# UART register map
Vendor: Texas Instruments
Peripheral module from a debugger description file (folder am437x).
Registers are 16-bit, access per field, no defined reset value unless marked. A register's access mark holds for its fields unless they carry their own. Offsets are as the file gives them; lines under a group give offsets from that group; [hi:lo] are bit positions; {n}, {i} and the like mark numbered series; 'fields as' and 'values as' point back to an identical list; <NAME> marks a mode.

## UART
0x00 UART_IER_CIR 32-bit access not given
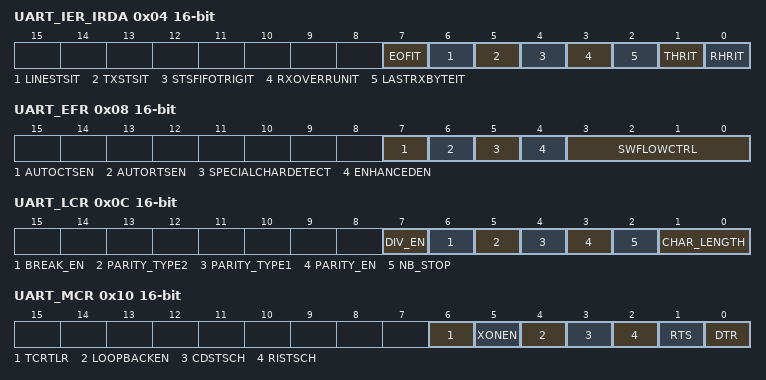
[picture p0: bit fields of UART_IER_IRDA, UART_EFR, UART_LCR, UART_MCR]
0x04 UART_IER_IRDA — The following interrupt enable register (IER) description is for IrDA mode. The IrDA IER is selected with a register bit setting of LCR[7] = 0. In IrDA mode, EFR[4] has no impact on the access to IER[7:4]. The IrDA interrupt enable register (IER) can be programmed to enable/disable any interrupt. There are 8 types of interrupt in these modes, received EOF, LSR interrupt, TX status, status FIFO interrupt, RX overrun, last byte in RX FIFO, THR interrupt, and RHR interrupt. Each interrupt can be enabled/disabled individually. The TXSTATUSIT interrupt reflects two possible conditions. The MDR2[0] bit should be read to determine the status in the event of this interrupt.
  [7] EOFIT rw
    1=en_2_0x1 (Enables the received EOF interrupt.); 0=en_1_0x0 (Disables the received EOF interrupt.)
  [6] LINESTSIT rw
    1=en_2_0x1 (Enables the receiver line status interrupt.); 0=en_1_0x0 (Disables the receiver line status interrupt.)
  [5] TXSTSIT rw — TXSTATUSIT
    1=en_2_0x1 (Enables the TX status interrupt.); 0=en_1_0x0 (Disables the TX status interrupt.)
  [4] STSFIFOTRIGIT rw
    1=en_2_0x1 (Enables status FIFO trigger level interrupt.); 0=en_1_0x0 (Disables status FIFO trigger level interrupt.)
  [3] RXOVERRUNIT rw
    1=en_2_0x1 (Enables the RX overrun interrupt.); 0=en_1_0x0 (Disables the RX overrun interrupt.)
  [2] LASTRXBYTEIT rw
    1=en_2_0x1 (Enables the last byte of frame in RX FIFO interrupt.); 0=en_1_0x0 (Disables the last byte of frame in RX FIFO interrupt.)
  [1] THRIT rw
    1=en_2_0x1 (Enables the THR interrupt.); 0=en_1_0x0 (Disables the THR interrupt.)
  [0] RHRIT rw
    1=en_2_0x1 (Enables the RHR interrupt.); 0=en_1_0x0 (Disables the RHR interrupt.)
0x08 UART_EFR — The enhanced feature register (EFR) is selected with a register bit setting of LCR[7] = BFh. The enhanced feature register (EFR) enables or disables enhanced features. Most enhanced functions apply only to UART modes, but EFR[4] enables write accesses to FCR[5:4], the TX trigger level, which is also used in IrDA modes.
  [7] AUTOCTSEN rw — Auto-CTS enable bit (UART mode only).
    1=en_2_0x1 (Auto-CTS flow control is enabled; transmission is halted when the CTS (active-low) pin is high (inactive).); 0=en_1_0x0 (Normal operation.)
  [6] AUTORTSEN rw — Auto-RTS enable bit (UART mode only).
    1=en_2_0x1 (Auto-RTS flow control is enabled; RTS (active-low) pin goes high (inactive) when the receiver FIFO HALT trigger level, TCR[3:0], is reached and goes low (active) when the receiver FIFO RESTORE transmission trigger level is reached.); 0=en_1_0x0 (Normal operation.)
  [5] SPECIALCHARDETECT rw — Special character detect (UART mode only).
    1=en_2_0x1 (Special character detect enable. Received data is compared with XOFF2 data. If a match occurs, the received data is transferred to RX FIFO and the IIR[4] bit is set to 1 to indicate that a special character was detected.); 0=en_1_0x0 (Normal operation.)
  [4] ENHANCEDEN rw — Enhanced functions write enable bit.
    1=en_2_0x1 (Enables writing to IER[7:4], FCR[5:4], and MCR[7:5].); 0=en_1_0x0 (Disables writing to IER[7:4], FCR[5:4], and MCR[7:5].)
  [3:0] SWFLOWCTRL rw — Combinations of software flow control can be selected by programming this bit. [[br]]XON1 and XON2 should be set to different values if the software flow control is enabled. [[br]]The TX and RX software flow control options are as follows. [[br]]EFR[3] = 0, EFR[2] = 0, EFR[1] = X, and EFR[0] = X, then: No transmit flow control. [[br]]EFR[3] = 1, EFR[2] = 0, EFR[1] = X, and EFR[0] = X, then: Transmit XON1, XOFF1. [[br]]EFR[3] = 0, EFR[2] = 1, EFR[1] = X, and EFR[0] = X, then: Transmit XON2, XOFF2. [[br]]EFR[3] = 1, EFR[2] = 1, EFR[1] = X, and EFR[0] = X, then: Transmit XON1, XON2 or XOFF1, XOFF2. [[br]]The XON1 and XON2 characters or the XOFF1 and XOFF2 characters must be transmitted/received sequentially with XON1/XOFF1 followed by XON2/XOFF2. [[br]]EFR[3] = X, EFR[2] = X, EFR[1] = 0, and EFR[0] = 0, then: No receive flow control. [[br]]EFR[3] = X, EFR[2] = X, EFR[1] = 1, and EFR[0] = 0, then: Receiver compares XON1, XOFF1. [[br]]EFR[3] = X, EFR[2] = X, EFR[1] = 0, and EFR[0] = 1, then: Receiver compares XON2, XOFF2. [[br]]EFR[3] = X, EFR[2] = X, EFR[1] = 1, and EFR[0] = 1, then: Receiver compares XON1, XON2 or XOFF1, XOFF2. [[br]]The XON1 and XON2 characters or the XOFF1 and XOFF2 characters must be transmitted/received sequentially with XON1/XOFF1 followed by XON2/XOFF2. [[br]]In IrDA mode, EFR[1] and EFR[0] select the IR address to check (see IR Address Checking).
0x0C UART_LCR — The line control register (LCR) is selected with a bit register setting of LCR[7] = 0, LCR[7] not equal to BFh, or LCR[7] = BFh. As soon as LCR[6] is set to 1, the TX line is forced to 0 and remains in this state as long as LCR[6] = 1.
  [7] DIV_EN rw — Divisor latch enable.
    1=en_2_0x1 (Divisor latch enable. Allows access to DLL and DLH.); 0=en_1_0x0 (Normal operating condition.)
  [6] BREAK_EN rw — Break control bit. [[br]]Note: When LCR[6] is set to 1, the TX line is forced to 0 and remains in this state as long as LCR[6] = 1.
    1=en_2_0x1 (Forces the transmitter output to go low to alert the communication terminal.); 0=en_1_0x0 (Normal operating condition.)
  [5] PARITY_TYPE2 rw — If LCR[3] = 1, then:
    1=en_2_0x1 (If LCR[5] = 1 and LCR[4] = 0, the parity bit is forced to 1 in the transmitted and received data. If LCR[5] = 1 and LCR[4] = 1, the parity bit is forced to 0 in the transmitted and received data.); 0=en_1_0x0 (If LCR[5] = 0, LCR[4] selects the forced parity format.)
  [4] PARITY_TYPE1 rw — If LCR[3] = 1, then:
    1=en_2_0x1 (Even parity is generated.); 0=en_1_0x0 (Odd parity is generated.)
  [3] PARITY_EN rw — Parity bit.
    1=en_2_0x1 (A parity bit is generated during transmission, and the receiver checks for received parity.); 0=en_1_0x0 (No parity.)
  [2] NB_STOP rw — Specifies the number of stop bits.
    1=en_2_0x1 (1.5 stop bits (word length = 5) or 2 stop bits (word length = 6, 7, 8).); 0=en_1_0x0 (1 stop bit (word length = 5, 6, 7, 8).)
  [1:0] CHAR_LENGTH rw — Specifies the word length to be transmitted or received.
    3=en_4_0x3 (8 bit); 2=en_3_0x2 (7 bits); 1=en_2_0x1 (6 bits); 0=en_1_0x0 (5 bits)
0x10 UART_MCR — The modem control register (MCR) is selected with a register bit setting of LCR[7] = 0 or LCR[7] not equal to BFh. MCR[7:5] can only be written when EFR[4] = 1. Bits 3-0 control the interface with the modem, data set, or peripheral device that is emulating the modem.
  [6] TCRTLR rw — Can be written only when EFR[4] = 1.
    1=en_2_0x1 (Enables access to the TCR and TLR registers.); 0=en_1_0x0 (No action.)
  [5] XONEN rw — Can be written only when EFR[4] = 1.
    1=en_2_0x1 (Enable XON any function.); 0=en_1_0x0 (Disable XON any function.)
  [4] LOOPBACKEN rw — Loopback mode enable.
    1=en_2_0x1 (Enable local loopback mode (internal). In this mode, the MCR[3:0] signals are looped back into MSR[7:4]. The transmit output is looped back to the receive input internally.); 0=en_1_0x0 (Normal operating mode.)
  [3] CDSTSCH rw
    1=en_2_0x1 (In loopback mode, forces DCD (active-low) input low and IRQ outputs to INACTIVE state.); 0=en_1_0x0 (In loopback mode, forces DCD (active-low) input high and IRQ outputs to INACTIVE state.)
  [2] RISTSCH rw
    1=en_2_0x1 (In loopback mode, forces RI (active-low) input active (low).); 0=en_1_0x0 (In loopback mode, forces RI (active-low) input inactive (high).)
  [1] RTS rw — In loopback mode, controls MSR[4]. [[br]]If auto-RTS is enabled, the RTS (active-low) output is controlled by hardware flow control.
    1=en_2_0x1 (Force RTS (active-low) output to active (low).); 0=en_1_0x0 (Force RTS (active-low) output to inactive (high).)
  [0] DTR rw
    1=en_2_0x1 (Force DTR (active-low) output (used in loopback mode) to active (low).); 0=en_1_0x0 (Force DTR (active-low) output (used in loopback mode) to inactive (high).)
0x14 UART_XON2_ADDR2 — The XON2/ADDR2 registers are selected with a register bit setting of LCR[7] = BFh. In UART mode, XON2 character; in IrDA mode, ADDR2 address 2.
  [7:0] XONWORD2 rw — Stores the 8 bit XON2 character in UART modes and ADDR2 address 2 in IrDA modes.
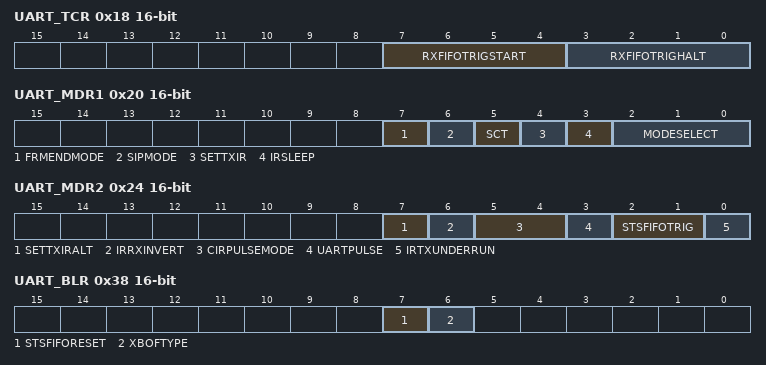
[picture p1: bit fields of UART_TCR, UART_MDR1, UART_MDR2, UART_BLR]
0x18 UART_TCR — The transmission control register (TCR) is selected with a register bit setting of LCR[7] = 0, LCR[7] not equal to BFh, or LCR[7] = BFh. The TCR is accessible only when EFR[4] = 1 and MCR[6] = 1. The transmission control register (TCR) stores the receive FIFO threshold levels to start/stop transmission during hardware flow control. Trigger levels from 0-60 bytes are available with a granularity of 4. Trigger level = 4 x [4-bit register value]. You must ensure that TCR[3:0] > TCR[7:4], whenever auto-RTS or software flow control is enabled to avoid a misoperation of the device. In FIFO interrupt mode with flow control, you have to also ensure that the trigger level to HALT transmission is greater or equal to receive FIFO trigger level (either TLR[7:4] or FCR[7:6]); otherwise, FIFO operation stalls. In FIFO DMA mode with flow control, this concept does not exist because the DMA request is sent each time a byte is received.
  [7:4] RXFIFOTRIGSTART rw — RX FIFO trigger level to RESTORE transmission (0 to 60).
  [3:0] RXFIFOTRIGHALT rw — RX FIFO trigger level to HALT transmission (0 to 60).
0x1C UART_SPR — The scratchpad register (SPR) is selected with a register bit setting of LCR[7] = 0 or LCR[7] not equal to BFh. The scratchpad register (SPR) is a read/write register that does not control the module. It is a scratchpad register used to hold temporary data.
  [7:0] SPR_WORD rw — Scratchpad register.
0x20 UART_MDR1 — The mode definition register 1 (MDR1) is selected with a register bit setting of LCR[7] = 0, LCR[7] not equal to BFh, or LCR[7] = BFh. The mode of operation is programmed by writing to MDR1[2:0]; therefore, the mode definition register 1 (MDR1) must be programmed on startup after configuration of the configuration registers (DLL, DLH, and LCR). The value of MDR1[2:0] must not be changed again during normal operation. If the module is disabled by setting the MODESELECT field to 7h, interrupt requests can still be generated unless disabled through the interrupt enable register (IER). In this case, UART mode interrupts are visible. Reading the interrupt identification register (IIR) shows the UART mode interrupt flags.
  [7] FRMENDMODE rw — IrDA mode only.
    1=en_2_0x1 (Set EOT bit method.); 0=en_1_0x0 (Frame-length method.)
  [6] SIPMODE rw — MIR/FIR modes only.
    1=en_2_0x1 (Automatic SIP mode: SIP is generated after each transmission.); 0=en_1_0x0 (Manual SIP mode: SIP is generated with the control of ACREG[3].)
  [5] SCT rw — Store and control the transmission.
    1=en_2_0x1 (Starts the infrared transmission with the control of ACREG[2]. Note: Before starting any transmission, there must be no reception ongoing.); 0=en_1_0x0 (Starts the infrared transmission when a value is written to the THR register.)
  [4] SETTXIR rw — Used to configure the infrared transceiver.
    1=en_2_0x1 (TXIR pin output is forced high (not dependant of MDR2[7] value).); 0=en_1_0x0 (If MDR2[7] = 0, no action; if MDR2[7] = 1, TXIR pin output is forced low.)
  [3] IRSLEEP rw — IrDA/CIR sleep mode.
    1=en_2_0x1 (IrDA/CIR sleep mode enabled.); 0=en_1_0x0 (IrDA/CIR sleep mode disabled.)
  [2:0] MODESELECT rw — UART/IrDA/CIR mode selection.
    7=en_8_0x7 (Disable (default state).); 6=en_7_0x6 (CIR mode.); 5=en_6_0x5 (FIR mode.); 4=en_5_0x4 (MIR mode.); 3=en_4_0x3 (UART 13x mode.); 2=en_3_0x2 (UART 16x auto-baud.); 1=en_2_0x1 (SIR mode.); 0=en_1_0x0 (UART 16x mode.)
0x24 UART_MDR2 — The mode definition register 2 (MDR2) is selected with a register bit setting of LCR[7] = 0, LCR[7] not equal to BFh, or LCR[7] = BFh. The MDR2[0] bit describes the status of the TX status interrupt in IIR[5]. The IRTXUNDERRUN bit must be read after a TX status interrupt occurs. The MDR2[2:1] bits set the trigger level for the frame status FIFO (8 entries) and must be programmed before the mode is programmed in MDR1[2:0]. The MDR2[6] bit gives the flexibility to invert the RX pin inside the UART module to ensure that the protocol at the input of the transceiver module has the same polarity at module level. By default, the RX pin is inverted because most of transceiver invert the IR receive pin.
  [7] SETTXIRALT rw — Provides alternate functionality for MDR1[4].
    1=en_2_0x1 (Alternate mode for SETTXIR); 0=en_1_0x0 (Normal mode)
  [6] IRRXINVERT rw — Only for IR mode (IrDA and CIR). [[br]]Invert RX pin in the module before the voting or sampling system logic of the infrared block. [[br]]This does not affect the RX path in UART modem modes.
    1=en_2_0x1 (No inversion is performed.); 0=en_1_0x0 (Inversion is performed.)
  [5:4] CIRPULSEMODE rw — CIR pulse modulation definition. [[br]]Defines high level of the pulse width associated with a digit:
    {v}=en_{v+1}_{0x0+v} (Pulse width of {v+3} from 12 cycles.) (v=0..3)
  [3] UARTPULSE rw — UART mode only. [[br]]Used to allow pulse shaping in UART mode.
    1=en_2_0x1 (UART mode with pulse shaping.); 0=en_1_0x0 (Normal UART mode.)
  [2:1] STSFIFOTRIG rw — Only for IrDA mode. [[br]]Frame status FIFO threshold select:
    3=en_4_0x3 (8 entries); 2=en_3_0x2 (7 entries); 1=en_2_0x1 (4 entries); 0=en_1_0x0 (1 entry)
  [0] IRTXUNDERRUN ro — IrDA transmission status interrupt. [[br]]When the TX status interrupt (IIR[5]) occurs, the meaning of the interrupt is:
    1=en_2_0x1 (An underrun occurred. The last bit of the frame was transmitted but with an underrun error. The bit is reset to 0 when the RESUME register is read.); 0=en_1_0x0 (The last bit of the frame was transmitted successfully without error.)
0x28 UART_TXFLL — The transmit frame length low register (TXFLL) is selected with a register bit setting of LCR[7] = 0, LCR[7] not equal to BFh, or LCR[7] = BFh. The transmit frame length low register (TXFLL) and the TXFLH register hold the 13-bit transmit frame length (expressed in bytes). TXFLL holds the LSBs and TXFLH holds the MSBs. The frame length value is used if the frame length method of frame closing is used.
  [7:0] TXFLL wo — LSB register used to specify the frame length.
0x2C UART_RESUME ro — The RESUME register is selected with a register bit setting of LCR[7] = 0, LCR[7] not equal to BFh, or LCR[7] = BFh. The RESUME register is used to clear internal flags, which halt transmission/reception when an underrun/overrun error occurs. Reading this register resumes the halted operation. This register does not physically exist and always reads as 00.
  [7:0] RESUME — Dummy read to restart the TX or RX, value 0 to FFh.
0x30 UART_RXFLL — The received frame length low register (RXFLL) is selected with a register bit setting of LCR[7] = 0, LCR[7] not equal to BFh, or LCR[7] = BFh. The received frame length low register (RXFLL) and the RXFLH register hold the 12-bit receive maximum frame length. RXFLL holds the LSBs and RXFLH holds the MSBs. If the intended maximum receive frame length is n bytes, program RXFLL and RXFLH to be n + 3 in SIR or MIR modes and n + 6 in FIR mode (+3 and +6 are the result of frame format with CRC and stop flag; two bytes are associated with the FIR stop flag).
  [7:0] RXFLL wo — LSB register used to specify the frame length in reception, value 0 to FFh.
0x34 UART_SFREGH ro — The status FIFO register high (SFREGH) is selected with a register bit setting of LCR[7] = 0, LCR[7] not equal to BFh, or LCR[7] = BFh. The frame lengths of received frames are written into the status FIFO. This information can be read by reading the status FIFO register low (SFREGL) and the status FIFO register high (SFREGH). These registers do not physically exist. The LSBs are read from SFREGL and the MSBs are read from SFREGH. Reading these registers does not alter the status FIFO read pointer. These registers must be read before the pointer is incremented by reading the SFLSR.
  [3:0] SFREGH — MSB part of the frame length, value 0 to Fh.
0x38 UART_BLR — The BOF control register (BLR) is selected with a register bit setting of LCR[7] = 0. The BLR[6] bit is used to select whether C0h or FFh start patterns are to be used, when multiple start flags are required in SIR mode. If only one start flag is required, this is always C0h. If n start flags are required, either (n - 1) C0h or (n -1) FFh flags are sent, followed by a single C0h flag (immediately preceding the first data byte).
  [7] STSFIFORESET rw — Status FIFO reset. [[br]]This bit is self-clearing.
  [6] XBOFTYPE rw — SIR xBOF select.
    1=en_2_0x1 (C0h start pattern is used.); 0=en_1_0x0 (FFh start pattern is used.)
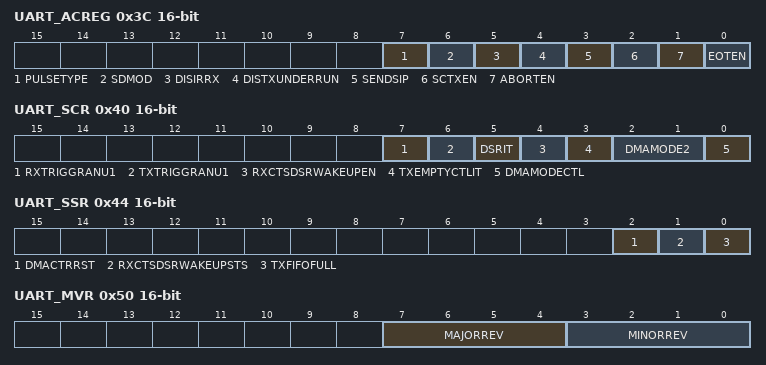
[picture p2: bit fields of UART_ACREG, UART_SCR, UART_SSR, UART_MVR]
0x3C UART_ACREG — The auxiliary control register (ACREG) is selected with a register bit setting of LCR[7] = 0. If transmit FIFO is not empty and MDR1[5] = 1, IrDA starts a new transfer with data of previous frame as soon as abort frame has been sent. Therefore, TX FIFO must be reset before sending an abort frame. It is recommended to disable TX FIFO underrun capability by masking corresponding underrun interrupt. When disabling underrun by setting ACREG[4] = 1, unknown data is sent over TX line.
  [7] PULSETYPE rw — SIR pulse-width select:
    1=en_2_0x1 (1.6 microseconds); 0=en_1_0x0 (3/16 of baud-rate pulse width)
  [6] SDMOD rw — Primary output used to configure transceivers. [[br]]Connected to the SD/MODE input pin of IrDA transceivers.
    1=en_2_0x1 (SD pin is set to low.); 0=en_1_0x0 (SD pin is set to high.)
  [5] DISIRRX rw — Disable RX input.
    1=en_2_0x1 (Disables RX input (permanent state; independent of transmit).); 0=en_1_0x0 (Normal operation (RX input automatically disabled during transmit, but enabled outside of transmit operation).)
  [4] DISTXUNDERRUN rw — Disable TX underrun.
    1=en_2_0x1 (Long stop bits can be transmitted.); 0=en_1_0x0 (Long stop bits cannot be transmitted. TX underrun is enabled.)
  [3] SENDSIP rw — MIR/FIR modes only. [[br]]Send serial infrared interaction pulse (SIP). [[br]]If this bit is set during an MIR/FIR transmission, the SIP is sent at the end of it. [[br]]This bit is automatically cleared at the end of the SIP transmission.
    1=en_2_0x1 (Send SIP pulse.); 0=en_1_0x0 (No action.)
  [2] SCTXEN rw — Store and control TX start. [[br]]When MDR1[5] = 1 and the LH writes 1 to this bit, the TX state-machine starts frame transmission. [[br]]This bit is self-clearing.
  [1] ABORTEN rw — Frame abort. [[br]]The LH can intentionally abort transmission of a frame by writing 1 to this bit. [[br]]Neither the end flag nor the CRC bits are appended to the frame.
  [0] EOTEN rw — EOT (end-of-transmission) bit. [[br]]The LH writes 1 to this bit just before it writes the last byte to the TX FIFO in the set-EOT bit frame-closing method. [[br]]This bit is automatically cleared when the LH writes to the THR (TX FIFO).
0x40 UART_SCR — The supplementary control register (SCR) is selected with a register bit setting of LCR[7] = 0, LCR[7] not equal to BFh, or LCR[7] = BFh. Bit 4 enables the wake-up interrupt, but this interrupt is not mapped into the IIR register. Therefore, when an interrupt occurs and there is no interrupt pending in the IIR register, the SSR[1] bit must be checked. To clear the wake-up interrupt, bit SCR[4] must be reset to 0.
  [7] RXTRIGGRANU1 rw
    1=en_2_0x1 (Enables the granularity of 1 for trigger RX level.); 0=en_1_0x0 (Disables the granularity of 1 for trigger RX level.)
  [6] TXTRIGGRANU1 rw
    1=en_2_0x1 (Enables the granularity of 1 for trigger TX level.); 0=en_1_0x0 (Disables the granularity of 1 for trigger TX level.)
  [5] DSRIT rw
    1=en_2_0x1 (Enables DSR (active-low) interrupt.); 0=en_1_0x0 (Disables DSR (active-low) interrupt.)
  [4] RXCTSDSRWAKEUPEN rw — RX CTS wake-up enable.
    1=en_2_0x1 (Waits for a falling edge of RX, CTS (active-low), or DSR (active-low) pins to generate an interrupt.); 0=en_1_0x0 (Disables the WAKE UP interrupt and clears SSR[1].)
  [3] TXEMPTYCTLIT rw
    1=en_2_0x1 (THR interrupt is generated when TX FIFO and TX shift register are empty.); 0=en_1_0x0 (Normal mode for THR interrupt.)
  [2:1] DMAMODE2 rw — Specifies the DMA mode valid if SCR[0] = 1, then:
    3=en_4_0x3 (DMA mode 3 (UARTnDMAREQ[0] in TX)); 2=en_3_0x2 (DMA mode 2 (UARTnDMAREQ[0] in RX)); 1=en_2_0x1 (DMA mode 1 (UARTnDMAREQ[0] in TX, UARTnDMAREQ[1] in RX)); 0=en_1_0x0 (DMA mode 0 (no DMA).)
  [0] DMAMODECTL rw — DMAMODECT
    1=en_2_0x1 (The DMAMODE is set with SCR[2:1].); 0=en_1_0x0 (The DMAMODE is set with FCR[3].)
0x44 UART_SSR — The supplementary status register (SSR) is selected with a register bit setting of LCR[7] = 0, LCR[7] not equal to BFh, or LCR[7] = BFh. Bit 1 is reset only when SCR[4] is reset to 0.
  [2] DMACTRRST rw — DMACOUNTERRST.
    1=en_2_0x1 (The DMA counter will be reset, if the corresponding FIFO is reset (via FCR[1] or FCR[2]).); 0=en_1_0x0 (The DMA counter will not be reset, if the corresponding FIFO is reset (via FCR[1] or FCR[2]).)
  [1] RXCTSDSRWAKEUPSTS ro — Pin falling edge detection: Reset only when SCR[4] is reset to 0.
    1=en_2_0x1 (A falling edge occurred on RX, CTS (active-low), or DSR (active-low).); 0=en_1_0x0 (No falling-edge event on RX, CTS (active-low), and DSR (active-low).)
  [0] TXFIFOFULL ro
    1=en_2_0x1 (TX FIFO is full.); 0=en_1_0x0 (TX FIFO is not full.)
0x48 UART_EBLR — The BOF length register (EBLR) is selected with a register bit setting of LCR[7] = 0. In IrDA SIR operation, the BOF length register (EBLR) specifies the number of BOF + xBOFs to transmit. The value set into this register must consider the BOF character; therefore, to send only one BOF with no XBOF, this register must be set to 1. To send one BOF with n XBOFs, this register must be set to n + 1. Furthermore, the value 0 sends 1 BOF plus 255 XBOFs. In IrDA MIR mode, the BOF length register (EBLR) specifies the number of additional start flags (MIR protocol mandates a minimum of 2 start flags). In CIR mode, the BOF length register (EBLR) specifies the number of consecutive zeros to be received before generating the RXSTOP interrupt (IIR[2]). All the received zeros are stored in the RX FIFO. When the register is cleared to 0, this feature is deactivated and always in reception state, which is disabled by setting the ACREG[5] bit to 1. If the RX_STOP interrupt occurs before a byte boundary, the remaining bits of the last byte are filled with zeros and then passed into the RX FIFO.
  [7:0] EBLR rw — IrDA mode: This register allows definition of up to 176 xBOFs, the maximum required by IrDA specification. [[br]]CIR mode: This register specifies the number of consecutive zeros to be received before generating the RXSTOP interrupt (IIR[2]). [[br]]
    255=en_3_0xFF (Generate RXSTOP interrupt after receiving 255 zero bits.); 1=en_2_0x1 (Generate RXSTOP interrupt after receiving 1 zero bit.); 0=en_1_0x0 (Feature disabled.)
0x50 UART_MVR ro — The module version register (MVR) is selected with a register bit setting of LCR[7] = 0, LCR[7] not equal to BFh, or LCR[7] = BFh. The reset value is fixed by hardware and corresponds to the RTL revision of this module. A reset has no effect on the value returned.
  [7:4] MAJORREV — Major revision number of the module.
  [3:0] MINORREV — Minor revision number of the module.
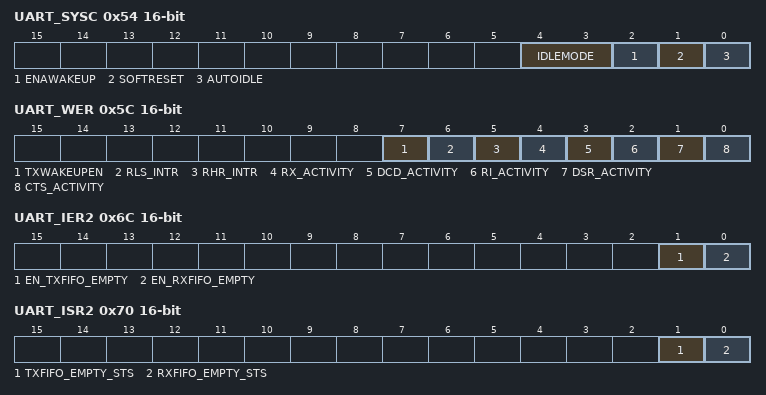
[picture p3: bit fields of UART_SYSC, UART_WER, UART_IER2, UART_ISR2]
0x54 UART_SYSC — The system configuration register (SYSC) is selected with a register bit setting of LCR[7] = 0, LCR[7] not equal to BFh, or LCR[7] = BFh. The AUTOIDLE bit controls a power-saving technique to reduce the logic power consumption of the module interface; that is, when the feature is enabled, the interface clock is gated off until the module interface is accessed. When the SOFTRESET bit is set high, it causes a full device reset.
  [4:3] IDLEMODE rw — Power management req/ack control.
    3=en_4_0x3 (Smart idle Wakeup: Acknowledgement to an idle request is given based in the internal activity of the module. The module is allowed to generate wakeup request. Only available on UART0.); 2=en_3_0x2 (Smart idle: Acknowledgement to an idle request is given based in the internal activity of the module.); 1=en_2_0x1 (No-idle: Idle request is never acknowledged.); 0=en_1_0x0 (Force idle: Idle request is acknowledged unconditionally.)
  [2] ENAWAKEUP rw — Wakeup control.
    1=en_2_0x1 (Wakeup capability is enabled.); 0=en_1_0x0 (Wakeup is disabled.)
  [1] SOFTRESET rw — Software reset. [[br]]Set this bit to 1 to trigger a module reset. [[br]]This bit is automatically reset by the hardware. [[br]]Read returns 0.
    1=en_2_0x1 (Module is reset.); 0=en_1_0x0 (Normal mode.)
  [0] AUTOIDLE rw — Internal interface clock-gating strategy.
    1=en_2_0x1 (Reserved.); 0=en_1_0x0 (Clock is running.)
0x58 UART_SYSS ro — The system status register (SYSS) is selected with a register bit setting of LCR[7] = 0, LCR[7] not equal to BFh, or LCR[7] = BFh.
  [0] RESETDONE — Internal reset monitoring.
    1=en_2_0x1 (Reset complete.); 0=en_1_0x0 (Internal module reset is ongoing.)
0x5C UART_WER — The wake-up enable register (WER) is selected with a register bit setting of LCR[7] = 0, LCR[7] not equal to BFh, or LCR[7] = BFh. The wake-up enable register (WER) is used to mask and unmask a UART event that subsequently notifies the system. An event is any activity in the logic that can cause an interrupt and/or an activity that requires the system to wake up. Even if wakeup is disabled for certain events, if these events are also an interrupt to the UART, the UART still registers the interrupt as such.
  [7] TXWAKEUPEN rw — Wake-up interrupt.
    1=en_2_0x1 (Event can wake up the system: Event can be: THRIT or TXDMA request and/or TXSATUSIT.); 0=en_1_0x0 (Event is not allowed to wake up the system.)
  [6] RLS_INTR rw — Receiver line status interrupt.
    1=en_2_0x1 (Event can wake up the system.); 0=en_1_0x0 (Event is not allowed to wake up the system.)
  [5] RHR_INTR rw — RHR interrupt.
    values as RLS_INTR
  [4] RX_ACTIVITY rw
    values as RLS_INTR
  [3] DCD_ACTIVITY rw
    values as RLS_INTR
  [2] RI_ACTIVITY rw
    values as RLS_INTR
  [1] DSR_ACTIVITY rw
    values as RLS_INTR
  [0] CTS_ACTIVITY rw
    values as RLS_INTR
0x60 UART_CFPS — The carrier frequency prescaler register (CFPS) is selected with a register bit setting of LCR[7] = 0, LCR[7] not equal to BFh, or LCR[7] = BFh. Since the consumer IR (CIR) works at modulation rates of 30-56.8 kHz, the 48 MHz clock must be prescaled before the clock can drive the IR logic. The carrier frequency prescaler register (CFPS) sets the divisor rate to give a range to accommodate the remote control requirements in BAUD multiples of 12x. The value of the CFPS at reset is 105 decimal (69h), which equates to a 38.1 kHz output from starting conditions. The 48 MHz carrier is prescaled by the CFPS that is then divided by the 12x BAUD multiple.
  [7:0] CFPS rw — System clock frequency prescaler at (12x multiple). [[br]]CFPS = 0 is not supported. [[br]]Examples for CFPS values follow. [[br]]Target Frequency (kHz) = 30, CFPS (decimal) = 133, Actual Frequency (kHz) = 30.08. [[br]]Target Frequency (kHz) = 32.75, CFPS (decimal) = 122, Actual Frequency (kHz) = 32.79. [[br]]Target Frequency (kHz) = 36, CFPS (decimal) = 111, Actual Frequency (kHz) = 36.04. [[br]]Target Frequency (kHz) = 36.7, CFPS (decimal) = 109, Actual Frequency (kHz) = 36.69. [[br]]Target Frequency (kHz) = 38, CFPS (decimal) = 105, Actual Frequency (kHz) = 38.1. [[br]]Target Frequency (kHz) = 40, CFPS (decimal) = 100, Actual Frequency (kHz) = 40. [[br]]Target Frequency (kHz) = 56.8, CFPS (decimal) = 70, Actual Frequency (kHz) = 57.14.
0x64 UART_RXFIFO_LVL ro
  [7:0] RXFIFO_LVL — Level of the RX FIFO
0x68 UART_TXFIFO_LVL ro
  [7:0] TXFIFO_LVL — Level of the TX FIFO
0x6C UART_IER2 — The IER2 enables RX/TX FIFOs empty corresponding interrupts.
  [1] EN_TXFIFO_EMPTY rw
    1=en_2_0x1 (Enables EN_TXFIFO_EMPTY interrupt.); 0=en_1_0x0 (Disables EN_TXFIFO_EMPTY interrupt.)
  [0] EN_RXFIFO_EMPTY rw — Number of bits by characters.
    1=en_2_0x1 (Enables EN_RXFIFO_EMPTY interrupt.); 0=en_1_0x0 (Disables EN_RXFIFO_EMPTY interrupt.)
0x70 UART_ISR2 — The interrupt status register 2 (ISR2) is selected with a register bit setting of LCR[7] = 0, LCR[7] not equal to BFh, or LCR[7] = BFh. The ISR2 displays the status of RX/TX FIFOs empty corresponding interrupts.
  [1] TXFIFO_EMPTY_STS rw
    1=en_2_0x1 (TXFIFO_EMPTY interrupt pending.); 0=en_1_0x0 (TXFIFO_EMPTY interrupt not pending.)
  [0] RXFIFO_EMPTY_STS rw
    1=en_2_0x1 (RXFIFO_EMPTY interrupt pending.); 0=en_1_0x0 (RXFIFO_EMPTY interrupt not pending.)
0x74 UART_FREQ_SEL
  [7:0] FREQ_SEL rw — Sets the sample per bit if non default frequency is used. [[br]]MDR3[1] must be set to 1 after this value is set. [[br]]Must be equal or higher then 6.
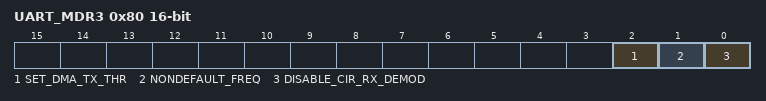
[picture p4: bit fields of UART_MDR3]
0x80 UART_MDR3 — The mode definition register 3 (MDR3) is selected with a register bit setting of LCR[7] = 0, LCR[7] not equal to BFh, or LCR[7] = BFh. The DISABLE_CIR_RX_DEMOD register bit will force the CIR receiver to bypass demodulation of received data if set. See the CIR Mode Block Components. The NONDEFAULT_FREQ register bit allows the user to set sample per bit by writing it into FREQ_SEL register. Set it if non-default (48 MHz) fclk frequency is used to achieve a less than 2% error rate. Changing this bit (to any value) will automatically disable the device by setting MDR[2:0] to 111 .
  [2] SET_DMA_TX_THR rw — SET_DMA_TX_THRESHOLD.
    1=en_2_0x1 (Enable to set different TX DMA threshold in the TX DMA Threshold register.); 0=en_1_0x0 (Disable use of TX DMA Threshold register. Use 64-TX trigger as DMA threshold.)
  [1] NONDEFAULT_FREQ rw
    1=en_2_0x1 (Enables using NONDEFAULT fclk frequencies (set FREQ_SEL and DLH/DLL).); 0=en_1_0x0 (Disables using NONDEFAULT fclk frequencies.)
  [0] DISABLE_CIR_RX_DEMOD rw
    1=en_2_0x1 (Disables CIR RX demodulation.); 0=en_1_0x0 (Enables CIR RX demodulation.)
0x84 UART_TX_DMA_THR — The TX DMA threshold register is selected with a register bit setting of LCR[7] = 0, LCR[7] not equal to BFh, or LCR[7] = BFh.
  [5:0] TX_DMA_THR rw — Used to manually set the TX DMA threshold level. [[br]]UART_MDR3[2] SET_TX_DMA_THRESHOLD must be 1 and must be value + tx_trigger_level = 64 (TX FIFO size). [[br]]If not, 64_tx_trigger_level will be used without modifying the value of this register.
